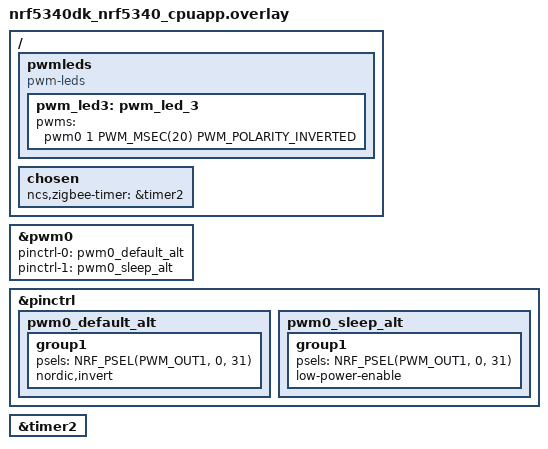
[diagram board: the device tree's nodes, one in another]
/*
 * Copyright (c) 2020-2022 Nordic Semiconductor ASA
 *
 * SPDX-License-Identifier: LicenseRef-Nordic-5-Clause
 */

/ {
	pwmleds {
		compatible = "pwm-leds";
		pwm_led3: pwm_led_3 {
			pwms = <&pwm0 1 PWM_MSEC(20) PWM_POLARITY_INVERTED>;
		};
	};

	chosen {
		ncs,zigbee-timer = &timer2;
	};
};

&pwm0 {
	pinctrl-0 = <&pwm0_default_alt>;
	pinctrl-1 = <&pwm0_sleep_alt>;
	pinctrl-names = "default", "sleep";
};

&pinctrl {
	pwm0_default_alt: pwm0_default_alt {
		group1 {
			psels = <NRF_PSEL(PWM_OUT1, 0, 31)>;
			nordic,invert;
		};
	};

	pwm0_sleep_alt: pwm0_sleep_alt {
		group1 {
			psels = <NRF_PSEL(PWM_OUT1, 0, 31)>;
			low-power-enable;
		};
	};

};

&timer2 {
	status = "okay";
};
